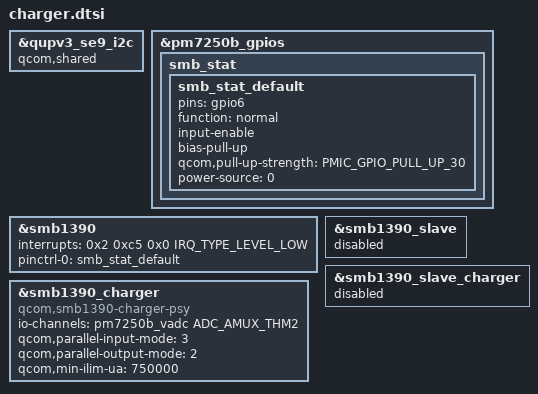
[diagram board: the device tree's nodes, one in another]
/*
 * nubia overwrite dts
 */

&qupv3_se9_i2c {
	/* Multi-ee usecase */
	qcom,shared;
};

&pm7250b_gpios {
	smb_stat {
		smb_stat_default: smb_stat_default {
			pins = "gpio6";
			function = "normal";
			input-enable;
			bias-pull-up;
			qcom,pull-up-strength = <PMIC_GPIO_PULL_UP_30>;
			power-source = <0>;
		};
	};
};

&qupv3_se9_i2c {
	status = "ok";
	#include "../../qcom/smb1390.dtsi"
};

&smb1390 {
	//delete-property/ interrupts;
	interrupts = <0x2 0xc5 0x0 IRQ_TYPE_LEVEL_LOW>;
	pinctrl-names = "default";
	pinctrl-0 = <&smb_stat_default>;
	status = "ok";
};

&smb1390_charger {
	compatible = "qcom,smb1390-charger-psy";
	io-channels = <&pm7250b_vadc ADC_AMUX_THM2>;
	io-channel-names = "cp_die_temp";
	//qcom,parallel-input-mode = <1>; /* USBIN */
	qcom,parallel-input-mode = <3>; /* USBIN */
	qcom,parallel-output-mode = <2>; /* VBAT */
	qcom,min-ilim-ua=<750000>;
	status = "ok";
};

&smb1390_slave {
	//status = "ok";
	status = "disabled";
};

&smb1390_slave_charger {
	//status = "ok";
	status = "disabled";
};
